# MCSPI register map
Vendor: Texas Instruments
Peripheral module from a debugger description file (folder am437x).
Registers are 32-bit, read-write, no defined reset value unless marked. A register's access mark holds for its fields unless they carry their own. Offsets are as the file gives them; lines under a group give offsets from that group; [hi:lo] are bit positions; {n}, {i} and the like mark numbered series; 'fields as' and 'values as' point back to an identical list; <NAME> marks a mode.

## MCSPI
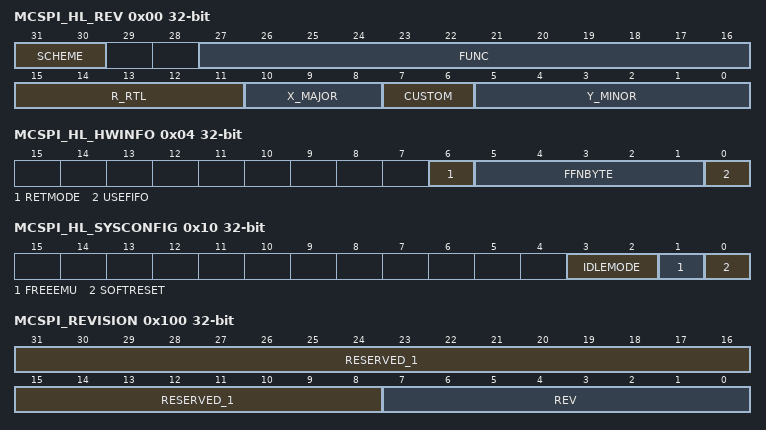
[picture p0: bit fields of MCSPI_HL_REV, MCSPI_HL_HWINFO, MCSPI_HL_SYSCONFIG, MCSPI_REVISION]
0x00 MCSPI_HL_REV ro — IP Revision Identifier (X.Y.R) Used by software to track features, bugs, and compatibility
  [31:30] SCHEME — Used to distinguish between old scheme and current.
    1=en_2_0x1 (Highlander 0.8 scheme); 0=en_1_0x0 (Legacy ASP or WTBU scheme)
  [27:16] FUNC — Function indicates a software compatible module family. [[br]]If there is no level of software compatibility a new Func number (and hence REVISION) should be assigned.
  [15:11] R_RTL — RTL Version (R), maintained by IP design owner. [[br]]RTL follows a numbering such as X.Y.R.Z which are explained in this table. [[br]]R changes ONLY when: (1) PDS uploads occur which may have been due to spec changes (2) Bug fixes occur (3) Resets to '0' when X or Y changes. [[br]]Design team has an internal 'Z' (customer invisible) number which increments on every drop that happens due to DV and RTL updates. [[br]]Z resets to 0 when R increments.
  [10:8] X_MAJOR — Major Revision (X), maintained by IP specification owner. [[br]]X changes ONLY when: (1) There is a major feature addition. [[br]]An example would be adding Master Mode to Utopia Level2. [[br]]The Func field (or Class/Type in old PID format) will remain the same. [[br]]X does NOT change due to: (1) Bug fixes (2) Change in feature parameters.
  [7:6] CUSTOM — Indicates a special version for a particular device. [[br]]Consequence of use may avoid use of standard Chip Support Library (CSL) / Drivers.
    0=en_1_0x0 (Non custom (standard) revision)
  [5:0] Y_MINOR — Minor Revision (Y), maintained by IP specification owner. [[br]]Y changes ONLY when: (1) Features are scaled (up or down). [[br]]Flexibility exists in that this feature scalability may either be represented in the Y change or a specific register in the IP that indicates which features are exactly available. [[br]](2) When feature creeps from Is-Not list to Is list. [[br]]But this may not be the case once it sees silicon[[br]] in which case X will change. [[br]]Y does NOT change due to: (1) Bug fixes (2) Typos or clarifications (3) major functional/feature change/addition/deletion. [[br]]Instead these changes may be reflected via R, S, X as applicable. [[br]]Spec owner maintains a customer-invisible number 'S' which changes due to: (1) Typos/clarifications (2) Bug documentation. [[br]]Note that this bug is not due to a spec change but due to implementation. [[br]]Nevertheless, the spec tracks the IP bugs. [[br]]An RTL release (say for silicon PG1.1) that occurs due to bug fix should document the corresponding spec number (X.Y.S) in its release notes.
0x04 MCSPI_HL_HWINFO ro — Information about the IP module's hardware configuration, i.e. typically the module's HDL generics (if any). Actual field format and encoding is up to the module's designer to decide.
  [6] RETMODE — This bit field indicates whether the retention mode is supported using the pin PIRFFRET.
    1=en_2_0x1 (Retention mode enabled); 0=en_1_0x0 (Retention mode disabled)
  [5:1] FFNBYTE — FIFO number of byte generic parameter This register defines the value of FFNBYTE generic parameter, only MSB bits from 8 down to 4 are taken into account.
    16=en_5_0x10 (FIFO 256 bytes depth); 8=en_4_0x8 (FIFO 128 bytes depth); 4=en_3_0x4 (FIFO 64 bytes depth); 2=en_2_0x2 (FIFO 32 bytes depth); 1=en_1_0x1 (FIFO 16 bytes depth)
  [0] USEFIFO — Use of a FIFO enable: This bit field indicates if a FIFO is integrated within controller design with its management.
    1=en_2_0x1 (FIFO and its management implemented in design with depth defined by FFNBYTE generic.); 0=en_1_0x0 (FIFO not implemented in design)
0x10 MCSPI_HL_SYSCONFIG access per field — Clock management configuration
  [3:2] IDLEMODE rw — Configuration of the local target state management mode. [[br]]By definition, target can handle read/write transaction as long as it is out of IDLE state.
    3=en_4_0x3 (Smart-idle wakeup-capable mode: local target's idle state eventually follows (acknowledges) the system's idle requests, depending on the IP module's internal requirements.IP module may generate (IRQ- or DMA-request-related) wakeup events when in idle state.Mode is only relevant if the appropriate IP module "swakeup" output(s) is (are) implemented.); 2=en_3_0x2 (Smart-idle mode: local target's idle state eventually follows (acknowledges) the system's idle requests, depending on the IP module's internal requirements.IP module shall not generate (IRQ- or DMA-request-related) wakeup events.); 1=en_2_0x1 (No-idle mode: local target never enters idle state.Backup mode, for debug only.); 0=en_1_0x0 (Force-idle mode: local target's idle state follows (acknowledges) the system's idle requests unconditionally, i.e. regardless of the IP module's internal requirements.Backup mode, for debug only.)
  [1] FREEEMU rw — Sensitivity to emulation (debug) suspend input signal.
    1=en_2_0x1 (IP module is not sensitive to emulation suspend); 0=en_1_0x0 (IP module is sensitive to emulation suspend)
  [0] SOFTRESET rw — Software reset. [[br]](Optional)
    1=en_4_0x1 (Initiate software reset); 1=en_3_0x1 (Reset (software or other) ongoing); 0=en_2_0x0 (No action); 0=en_1_0x0 (Reset done, no pending action)
0x100 MCSPI_REVISION ro — This register contains the hard coded RTL revision number.
  [31:8] RESERVED_1 — Reads returns 0
  [7:0] REV — IP revision [[br]][7:4] Major revision [[br]][3:0] Minor revision Examples: 0x10 for 1.0, 0x21 for 2.1
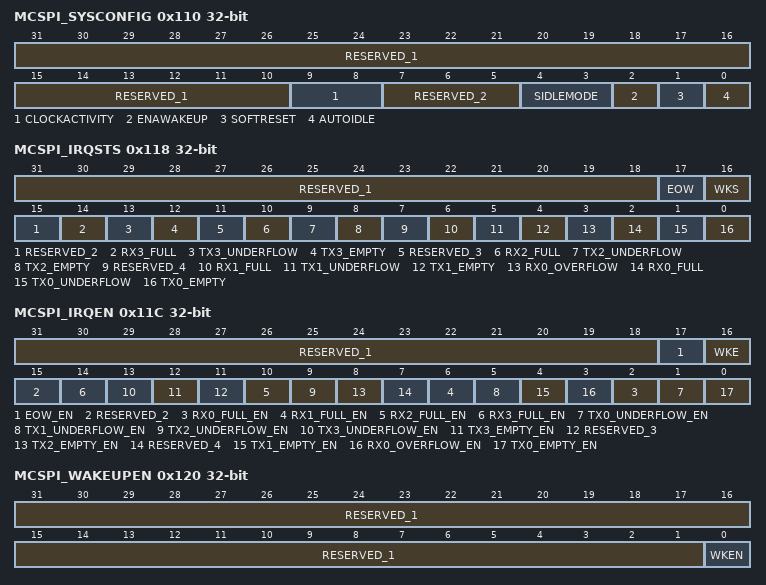
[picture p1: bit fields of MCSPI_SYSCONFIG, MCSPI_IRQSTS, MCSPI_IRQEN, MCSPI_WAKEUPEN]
0x110 MCSPI_SYSCONFIG — This register allows controlling various parameters of the OCP interface.
  [31:10] RESERVED_1 — Reads returns 0
  [9:8] CLOCKACTIVITY — Clocks activity during wake up mode period
    3=en_4_0x3 (OCP and Functional clocks are maintained.); 2=en_3_0x2 (Functional clock is maintained. OCP clock may be switched-off.); 1=en_2_0x1 (OCP clock is maintained. Functional clock may be switched-off.); 0=en_1_0x0 (OCP and Functional clocks may be switched off.)
  [7:5] RESERVED_2 — Reads returns 0
  [4:3] SIDLEMODE — Power management
    3=en_4_0x3 (If an idle request is detected, the module will switch to idle mode based on its internal activity, and the wake up capability can be used if the bit MCSPI_SYSCONFIG[EnaWakeUp] is set.); 2=en_3_0x2 (If an idle request is detected, the module will switch to idle mode based on its internal activity. The wake up capability cannot be used.); 1=en_2_0x1 (If an idle request is detected, the request is ignored and the module does not switch to wake up mode, and keeps on behaving normally.); 0=en_1_0x0 (If an idle request is detected, the McSPI acknowledges it unconditionally and goes in Inactive mode. Interrupt, DMA requests and wake up lines are unconditionally de-asserted and the module wakeup capability is deactivated even if the bit MCSPI_SYSCONFIG[EnaWakeUp] is set.)
  [2] ENAWAKEUP — WakeUp feature control
    1=en_2_0x1 (WakeUp capability is enabled); 0=en_1_0x0 (WakeUp capability is disabled)
  [1] SOFTRESET — Software reset. [[br]]During reads it always returns 0.
    1=en_2_0x1 ((write) Set this bit to 1 to trigger a module reset.The bit is automatically reset by the hardware.); 0=en_1_0x0 ((write) Normal mode)
  [0] AUTOIDLE — Internal OCP Clock gating strategy
    1=en_2_0x1 (Automatic OCP clock gating strategy is applied, based on the OCP interface activity); 0=en_1_0x0 (OCP clock is free-running)
0x114 MCSPI_SYSSTS ro — This register provides status information about the module excluding the interrupt status information
  [0] RESETDONE — Internal Reset Monitoring
    1=en_2_0x1 (Reset completed); 0=en_1_0x0 (Internal module reset is on-going)
0x118 MCSPI_IRQSTS — The interrupt status regroups all the status of the module internal events that can generate an interrupt
  [31:18] RESERVED_1 — Reads returns 0
  [17] EOW — End of word count event when a channel is enabled using the FIFO buffer and the channel had sent the number of SPI word defined by MCSPI_XFERLEVEL[WCNT]. [[br]]
    1=en_4_0x1 (Event is pending); 1=en_3_0x1 (Event status bit is reset); 0=en_2_0x0 (Event status bit unchanged); 0=en_1_0x0 (Event false)
  [16] WKS — Wake Up event in slave mode when an active control signal is detected on the SPIEN line programmed in the field MCSPI_CH0CONF[SPIENSLV]
    values as EOW
  [15] RESERVED_2 — Reads returns 0
  [14] RX3_FULL — Receiver register is full or almost full. [[br]]Only when Channel 3 is enabled
    values as EOW
  [13] TX3_UNDERFLOW — Transmitter register underflow. [[br]]Only when Channel 3 is enabled. [[br]]The transmitter register is empty (not updated by Host or DMA with new data) before its time slot assignment. [[br]]Exception: No TX_underflow event when no data has been loaded into the transmitter register since channel has been enabled. [[br]]
    values as EOW
  [12] TX3_EMPTY — Transmitter register is empty or almost empty. [[br]]Note: Enabling the channel automatically rises this event. [[br]]
    values as EOW
  [11] RESERVED_3 — Reads returns 0
  [10] RX2_FULL — Receiver register full or almost full. [[br]]Channel 2
    values as EOW
  [9] TX2_UNDERFLOW — Transmitter register underflow. [[br]]Channel 2
    values as EOW
  [8] TX2_EMPTY — Transmitter register empty or almost empty. [[br]]Channel 2
    values as EOW
  [7] RESERVED_4 — Reads returns 0
  [6] RX1_FULL — Receiver register full or almost full. [[br]]Channel 1
    values as EOW
  [5] TX1_UNDERFLOW — Transmitter register underflow. [[br]]Channel 1
    values as EOW
  [4] TX1_EMPTY — Transmitter register empty or almost empty. [[br]]Channel 1
    values as EOW
  [3] RX0_OVERFLOW — Receiver register overflow (slave mode only). [[br]]Channel 0
    values as EOW
  [2] RX0_FULL — Receiver register full or almost full. [[br]]Channel 0
    values as EOW
  [1] TX0_UNDERFLOW — Transmitter register underflow. [[br]]Channel 0
    values as EOW
  [0] TX0_EMPTY — Transmitter register empty or almost empty. [[br]]Channel 0
    values as EOW
0x11C MCSPI_IRQEN — This register allows to enable/disable the module internal sources of interrupt, on an event-by-event basis.
  [31:18] RESERVED_1 — Reads return 0
  [17] EOW_EN — End of Word count Interrupt Enable.
    1=en_2_0x1 (Interrupt enabled); 0=en_1_0x0 (Interrupt disabled)
  [16] WKE — Wake Up event interrupt Enable in slave mode when an active control signal is detected on the SPIEN line programmed in the field MCSPI_CH0CONF[SPIENSLV]
    values as EOW_EN
  [15] RESERVED_2 — Reads returns 0
  [4n+2] RX{n}_FULL_EN (n=0..3) — Receiver register Full Interrupt Enable. [[br]]Ch {n}
    values as EOW_EN
  [4n+1] TX{n}_UNDERFLOW_EN (n=0..3) — Transmitter register Underflow Interrupt Enable. [[br]]Ch {n}
    values as EOW_EN
  [12] TX3_EMPTY_EN — Transmitter register Empty Interrupt Enable. [[br]]Ch3
    values as EOW_EN
  [11] RESERVED_3 — Reads return 0
  [8] TX2_EMPTY_EN — Transmitter register Empty Interrupt Enable. [[br]]Ch 2
    values as EOW_EN
  [7] RESERVED_4 — Reads return 0
  [4] TX1_EMPTY_EN — Transmitter register Empty Interrupt Enable. [[br]]Ch 1
    values as EOW_EN
  [3] RX0_OVERFLOW_EN — Receiver register Overflow Interrupt Enable. [[br]]Ch 0
    values as EOW_EN
  [0] TX0_EMPTY_EN — Transmitter register Empty Interrupt Enable. [[br]]Ch 0
    values as EOW_EN
0x120 MCSPI_WAKEUPEN — The wakeup enable register allows to enable/disable the module internal sources of wakeup on event-by-event basis.
  [31:1] RESERVED_1 — Reads returns 0
  [0] WKEN — WakeUp functionality in slave mode when an active control signal is detected on the SPIEN line programmed in the field MCSPI_CH0CONF[SPIENSLV]
    1=en_2_0x1 (The event is allowed to wakeup the system if the global control bit MCSPI_SYSCONF[EnaWakeUp] is set.); 0=en_1_0x0 (The event is not allowed to wakeup the system, even if the global control bit MCSPI_SYSCONF[EnaWakeUp] is set.)
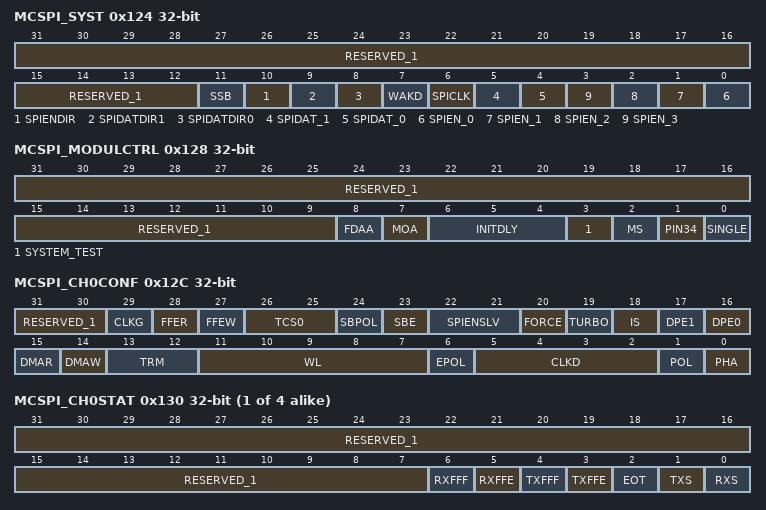
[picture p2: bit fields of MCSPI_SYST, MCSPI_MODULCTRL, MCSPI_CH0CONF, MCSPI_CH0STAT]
0x124 MCSPI_SYST — This register is used to check the correctness of the system interconnect either internally to peripheral bus, or externally to device IO pads, when the module is configured in system test (SYSTEST) mode.
  [31:12] RESERVED_1 — Reads returns 0
  [11] SSB — Set status bit
    1=en_2_0x1 (Force to 1 all status bits of MCSPI_IRQSTATUS register. Writing 1 into this bit sets to 1 all status bits contained in the MCSPI_IRQSTATUS register.); 0=en_1_0x0 (No action. Writing 0 does not clear already set status bits; This bit must be cleared prior attempting to clear a status bit of the MCSPI_IRQSTATUS register.)
  [10] SPIENDIR — Set the direction of the SPIEN[[br]][3:0] lines and SPICLK line
    1=en_2_0x1 (input (as in slave mode)); 0=en_1_0x0 (output (as in master mode))
  [9] SPIDATDIR1 — Set the direction of the SPIDAT[1]
    1=en_2_0x1 (input); 0=en_1_0x0 (output)
  [8] SPIDATDIR0 — Set the direction of the SPIDAT[0]
    1=en_2_0x1 (input); 0=en_1_0x0 (output)
  [7] WAKD — SWAKEUP output (signal data value of internal signal to system). [[br]]The signal is driven high or low according to the value written into this register bit.
    1=en_2_0x1 (The pin is driven high.); 0=en_1_0x0 (The pin is driven low.)
  [6] SPICLK — SPICLK line (signal data value) If MCSPI_SYST[SPIENDIR] = 1 (input mode direction), this bit returns the value on the CLKSPI line (high or low), and a write into this bit has no effect. [[br]]If MCSPI_SYST[SPIENDIR] = 0 (output mode direction), the CLKSPI line is driven high or low according to the value written into this register.
  [5] SPIDAT_1 — SPIDAT[1] line (signal data value) If MCSPI_SYST[SPIDATDIR1] = 0 (output mode direction), the SPIDAT[1] line is driven high or low according to the value written into this register. [[br]]If MCSPI_SYST[SPIDATDIR1] = 1 (input mode direction), this bit returns the value on the SPIDAT[1] line (high or low), and a write into this bit has no effect. [[br]]
  [4] SPIDAT_0 — SPIDAT[0] line (signal data value) If MCSPI_SYST[SPIDATDIR0] = 0 (output mode direction), the SPIDAT[0] line is driven high or low according to the value written into this register. [[br]]If MCSPI_SYST[SPIDATDIR0] = 1 (input mode direction), this bit returns the value on the SPIDAT[0] line (high or low), and a write into this bit has no effect. [[br]]
  [n] SPIEN_{n} (n=0..3) — SPIEN[{n}] line (signal data value) If MCSPI_SYST[SPIENDIR] = 0 (output mode direction), the SPIENT[{n}] line is driven high or low according to the value written into this register. [[br]]If MCSPI_SYST[SPIENDIR] = 1 (input mode direction), this bit returns the value on the SPIEN[{n}] line (high or low), and a write into this bit has no effect.
0x128 MCSPI_MODULCTRL — This register is dedicated to the configuration of the serial port interface.
  [31:9] RESERVED_1 — Reads returns 0
  [8] FDAA — FIFO DMA Address [[br]]256-bit aligned This register is used when a FIFO is managed by the module and DMA connected to the controller provides only 256 bit aligned address. [[br]]If this bit is set the enabled channel which uses the FIFO has its datas managed through MCSPI_DAFTX and MCSPI_DAFRX registers instead of MCSPI_TX(i) and MCSPI_RX(i) registers.
    1=en_2_0x1 (FIFO data managed by MCSPI_DAFTX and MCSPI_DAFRX registers.); 0=en_1_0x0 (FIFO data managed by MCSPI_TX(i) and MCSPI_RX(i) registers.)
  [7] MOA — Multiple word ocp access: This register can only be used when a channel is enabled using a FIFO. [[br]]It allows the system to perform multiple SPI word access for a single [[br]]32-bit OCP word access. [[br]]This is possible for WL less than 16.
    1=en_2_0x1 (Multiple word access enabled with FIFO); 0=en_1_0x0 (Multiple word access disabled)
  [6:4] INITDLY — Initial spi delay for first transfer: This register is an option only available in SINGLE master mode, The controller waits for a delay to transmit the first spi word after channel enabled and corresponding TX register filled. [[br]]This Delay is based on SPI output frequency clock, No clock output provided to the boundary and chip select is not active in 4 pin mode within this period. [[br]]
    4=en_5_0x4 (32ClkDly : The controller wait 32 spi bus clock); 3=en_4_0x3 (16ClkDly : The controller wait 16 spi bus clock); 2=en_3_0x2 (8ClkDly : The controller wait 8 spi bus clock); 1=en_2_0x1 (4ClkDly : The controller wait 4 spi bus clock); 0=en_1_0x0 (No delay for first spi transfer.)
  [3] SYSTEM_TEST — Enables the system test mode
    1=en_2_0x1 (System test mode (SYSTEST)); 0=en_1_0x0 (Functional mode)
  [2] MS — Master/ Slave
    1=en_2_0x1 (Slave - The module receives the SPICLK and SPIEN[3:0]); 0=en_1_0x0 (Master - The module generates the SPICLK and SPIEN[3:0])
  [1] PIN34 — Pin mode selection: This register is used to configure the SPI pin mode, in master or slave mode. [[br]]If asserted the controller only use SIMO,SOMI and SPICLK clock pin for spi transfers.
    1=en_2_0x1 (3PinMode : SPIEN is used as a chip select.); 0=en_1_0x0 (4PinMode : SPIEN is not used.In this mode all related option to chip select have no meaning.)
  [0] SINGLE — Single channel / Multi Channel (master mode only)
    1=en_2_0x1 (Only one channel will be used in master mode. This bit must be set in Force SPIEN mode.); 0=en_1_0x0 (More than one channel will be used in master mode.)
0x12C MCSPI_CH0CONF access per field — This register is dedicated to the configuration of the channel 0
  [31:30] RESERVED_1 ro — read returns 0
  [29] CLKG rw — Clock divider granularity This register defines the granularity of channel clock divider: power of two or one clock cycle granularity. [[br]]When this bit is set the register MCSPI_CHCTRL[EXTCLK] must be configured to reach a maximum of 4096 clock divider ratio. [[br]]Then The clock divider ratio is a concatenation of MCSPI_CHCONF[CLKD] and MCSPI_CHCTRL[EXTCLK] values
    1=en_2_0x1 (One clock cycle ganularity); 0=en_1_0x0 (Clock granularity of power of two)
  [28] FFER rw — FIFO enabled for receive:Only one channel can have this bit field set.
    1=en_2_0x1 (The buffer is used to receive data.); 0=en_1_0x0 (The buffer is not used to receive data.)
  [27] FFEW rw — FIFO enabled for Transmit:Only one channel can have this bit field set.
    1=en_2_0x1 (The buffer is used to transmit data.); 0=en_1_0x0 (The buffer is not used to transmit data.)
  [26:25] TCS0 rw — Chip Select Time Control This [[br]]2-bits field defines the number of interface clock cycles between CS toggling and first or last edge of SPI clock.
    3=en_4_0x3 (3.5 clock cycle); 2=en_3_0x2 (2.5 clock cycle); 1=en_2_0x1 (1.5 clock cycle); 0=en_1_0x0 (0.5 clock cycle)
  [24] SBPOL rw — Start bit polarity
    1=en_2_0x1 (Start bit polarity is held to 1 during SPI transfer.); 0=en_1_0x0 (Start bit polarity is held to 0 during SPI transfer.)
  [23] SBE rw — Start bit enable for SPI transfer
    1=en_2_0x1 (Start bit D/CX added before SPI transfer polarity is defined by MCSPI_CH0CONF[SBPOL]); 0=en_1_0x0 (Default SPI transfer length as specified by WL bit field)
  [22:21] SPIENSLV rw — Channel 0 only and slave mode only: SPI slave select signal detection. [[br]]Reserved bits for other cases.
    {v}=en_{v+1}_{0x0+v} (Detection enabled only on SPIEN[{v}]) (v=0..3)
  [20] FORCE rw — Manual SPIEN assertion to keep SPIEN active between SPI words. [[br]](single channel master mode only)
    1=en_2_0x1 (Writing 1 into this bit drives high the SPIEN line when MCSPI_CHCONF(i)[EPOL]=0, and drives it low when MCSPI_CHCONF(i)[EPOL]=1); 0=en_1_0x0 (Writing 0 into this bit drives low the SPIEN line when MCSPI_CHCONF(i)[EPOL]=0, and drives it high when MCSPI_CHCONF(i)[EPOL]=1.)
  [19] TURBO rw — Turbo mode
    1=en_2_0x1 (Turbo is activated to maximize the throughput for multi SPI words transfer.); 0=en_1_0x0 (Turbo is deactivated (recommended for single SPI word transfer))
  [18] IS rw — Input Select
    1=en_2_0x1 (Data Line1 (SPIDAT[1]) selected for reception); 0=en_1_0x0 (Data Line0 (SPIDAT[0]) selected for reception.)
  [17] DPE1 rw — Transmission Enable for data line 1 (SPIDATAGZEN[1])
    1=en_2_0x1 (No transmission on Data Line1 (SPIDAT[1])); 0=en_1_0x0 (Data Line1 (SPIDAT[1]) selected for transmission)
  [16] DPE0 rw — Transmission Enable for data line 0 (SPIDATAGZEN[0])
    1=en_2_0x1 (No transmission on Data Line0 (SPIDAT[0])); 0=en_1_0x0 (Data Line0 (SPIDAT[0]) selected for transmission)
  [15] DMAR rw — DMA Read request The DMA Read request line is asserted when the channel is enabled and a new data is available in the receive register of the channel. [[br]]The DMA Read request line is deasserted on read completion of the receive register of the channel.
    1=en_2_0x1 (DMA Read Request enabled); 0=en_1_0x0 (DMA Read Request disabled)
  [14] DMAW rw — DMA Write request. [[br]]The DMA Write request line is asserted when The channel is enabled and the transmitter register of the channel is empty. [[br]]The DMA Write request line is deasserted on load completion of the transmitter register of the channel.
    1=en_2_0x1 (DMA Write Request enabled); 0=en_1_0x0 (DMA Write Request disabled)
  [13:12] TRM rw — Transmit/Receive modes
    3=en_4_0x3 (Reserved); 2=en_3_0x2 (Transmit only mode); 1=en_2_0x1 (Receive only mode); 0=en_1_0x0 (Transmit and Receive mode)
  [11:7] WL rw — SPI word length
    {v}=en_{v+1}_{0x0+v} ({v+1}bits : The SPI word is {v+1}-bits long) (v=3..31); 2=en_3_0x2 (Reserved); 1=en_2_0x1 (Reserved); 0=en_1_0x0 (Reserved)
  [6] EPOL rw — SPIEN polarity
    1=en_2_0x1 (SPIEN is held low during the active state.); 0=en_1_0x0 (SPIEN is held high during the active state.)
  [5:2] CLKD rw — Frequency divider for SPICLK. [[br]](only when the module is a Master SPI device). [[br]]A programmable clock divider divides the SPI reference clock (CLKSPIREF) with a [[br]]4-bit value, and results in a new clock SPICLK available to shift-in and shift-out data. [[br]]By default the clock divider ratio has a power of two granularity when MCSPI_CHCONF[CLKG] is cleared, Otherwise this register is the 4 LSB bit of a [[br]]12-bit register concatenated with clock divider extension MCSPI_CHCTRL[EXTCLK] register.The value description below defines the clock ratio when MCSPI_CHCONF[CLKG] is set to 0.
    15=en_16_0xF (32768); 14=en_15_0xE (16384); 13=en_14_0xD (8192); 12=en_13_0xC (4096); 11=en_12_0xB (2048); 10=en_11_0xA (1024); 9=en_10_0x9 (512); 8=en_9_0x8 (256); 7=en_8_0x7 (128); 6=en_7_0x6 (64); 5=en_6_0x5 (32); 4=en_5_0x4 (16); 3=en_4_0x3 (8); 2=en_3_0x2 (4); 1=en_2_0x1 (2); 0=en_1_0x0 (1)
  [1] POL rw — SPICLK polarity
    1=en_2_0x1 (SPICLK is held low during the active state); 0=en_1_0x0 (SPICLK is held high during the active state)
  [0] PHA rw — SPICLK phase
    1=en_2_0x1 (Data are latched on even numbered edges of SPICLK.); 0=en_1_0x0 (Data are latched on odd numbered edges of SPICLK.)
{0x130+0x14*i} MCSPI_CH{i}STAT ro (i=0..3) — This register provides status information about transmitter and receiver registers of channel {i}
  [31:7] RESERVED_1 — Read returns 0
  [6] RXFFF — Channel "i" FIFO Receive Buffer Full Status
    1=en_2_0x1 (FIFO Receive Buffer is full); 0=en_1_0x0 (FIFO Receive Buffer is not full)
  [5] RXFFE — Channel "i" FIFO Receive Buffer Empty Status
    1=en_2_0x1 (FIFO Receive Buffer is empty); 0=en_1_0x0 (FIFO Receive Buffer is not empty)
  [4] TXFFF — Channel "i" FIFO Transmit Buffer Full Status
    1=en_2_0x1 (FIFO Transmit Buffer is full); 0=en_1_0x0 (FIFO Transmit Buffer is not full)
  [3] TXFFE — Channel "i" FIFO Transmit Buffer Empty Status
    1=en_2_0x1 (FIFO Transmit Buffer is empty); 0=en_1_0x0 (FIFO Transmit Buffer is not empty)
  [2] EOT — Channel "i" End of transfer Status. [[br]]The definitions of beginning and end of transfer vary with master versus slave and the transfer format (Transmit/Receive modes, Turbo mode). [[br]]See dedicated chapters for details.
    1=en_2_0x1 (This flag is automatically set to one at the end of an SPI transfer.); 0=en_1_0x0 (This flag is automatically cleared when the shift register is loaded with the data from the transmitter register (beginning of transfer).)
  [1] TXS — Channel "i" Transmitter Register Status
    1=en_2_0x1 (Register is empty); 0=en_1_0x0 (Register is full)
  [0] RXS — Channel "i" Receiver Register Status
    1=en_2_0x1 (Register is full); 0=en_1_0x0 (Register is empty)
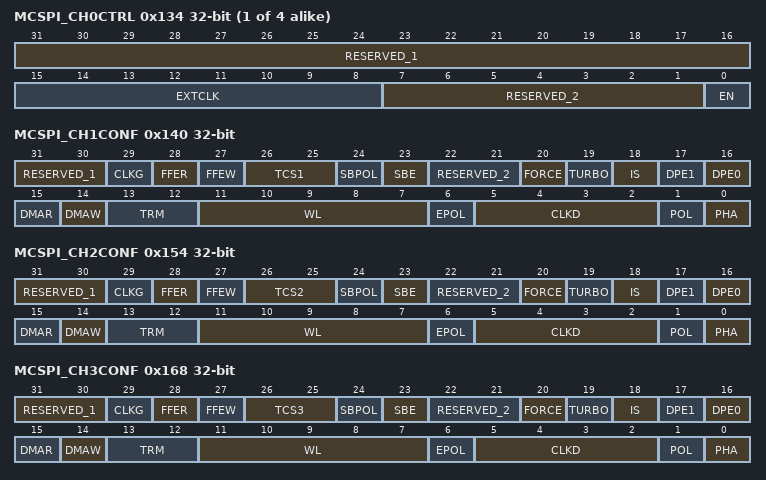
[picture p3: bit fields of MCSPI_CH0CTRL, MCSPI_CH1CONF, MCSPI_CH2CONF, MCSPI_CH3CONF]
{0x134+0x14*i} MCSPI_CH{i}CTRL (i=0..3) — This register is dedicated to enable the channel {i}
  [31:16] RESERVED_1 — Read returns 0
  [15:8] EXTCLK — Clock ratio extension: This register is used to concatenate with MCSPI_CHCONF[CLKD] register for clock ratio only when granularity is one clock cycle (MCSPI_CHCONF[CLKG] set to 1). [[br]]Then the max value reached is 4096 clock divider ratio.
    255=en_3_0xFF (Clock ratio is CLKD + 1 + 4080); 1=en_2_0x1 (Clock ratio is CLKD + 1 + 16); 0=en_1_0x0 (Clock ratio is CLKD + 1)
  [7:1] RESERVED_2 — Read returns 0
  [0] EN — Channel Enable
    1=en_2_0x1 (Channel "i" is active); 0=en_1_0x0 (Channel "i" is not active)
{0x138+0x14*i} MCSPI_TX{i} (i=0..3) — This register contains a single SPI word to transmit on the serial link, what ever SPI word length is.
  [31:0] TDATA — Channel {i} Data to transmit
{0x13C+0x14*i} MCSPI_RX{i} ro (i=0..3) — This register contains a single SPI word received through the serial link, what ever SPI word length is.
  [31:0] RDATA — Channel {i} Received Data
0x140 MCSPI_CH1CONF — This register is dedicated to the configuration of the channel.
  [31:30] RESERVED_1 — read returns 0
  [29] CLKG — Clock divider granularity This register defines the granularity of channel clock divider: power of two or one clock cycle granularity. [[br]]When this bit is set the register MCSPI_CHCTRL[EXTCLK] must be configured to reach a maximum of 4096 clock divider ratio. [[br]]Then The clock divider ratio is a concatenation of MCSPI_CHCONF[CLKD] and MCSPI_CHCTRL[EXTCLK] values
    values as MCSPI_CH0CONF.CLKG
  [28] FFER — FIFO enabled for receive:Only one channel can have this bit field set.
    values as MCSPI_CH0CONF.FFER
  [27] FFEW — FIFO enabled for Transmit:Only one channel can have this bit field set.
    values as MCSPI_CH0CONF.FFEW
  [26:25] TCS1 — Chip Select Time Control This [[br]]2-bits field defines the number of interface clock cycles between CS toggling and first or last edge of SPI clock.
    values as MCSPI_CH0CONF.TCS0
  [24] SBPOL — Start bit polarity
    values as MCSPI_CH0CONF.SBPOL
  [23] SBE — Start bit enable for SPI transfer
    1=en_2_0x1 (Start bit D/CX added before SPI transfer polarity is defined by MCSPI_CH1CONF[SBPOL]); 0=en_1_0x0 (Default SPI transfer length as specified by WL bit field)
  [22:21] RESERVED_2 — read returns 0
  [20] FORCE — Manual SPIEN assertion to keep SPIEN active between SPI words. [[br]](single channel master mode only)
    values as MCSPI_CH0CONF.FORCE
  [19] TURBO — Turbo mode
    values as MCSPI_CH0CONF.TURBO
  [18] IS — Input Select
    values as MCSPI_CH0CONF.IS
  [17] DPE1 — Transmission Enable for data line 1 (SPIDATAGZEN[1])
    values as MCSPI_CH0CONF.DPE1
  [16] DPE0 — Transmission Enable for data line 0 (SPIDATAGZEN[0])
    values as MCSPI_CH0CONF.DPE0
  [15] DMAR — DMA Read request The DMA Read request line is asserted when the channel is enabled and a new data is available in the receive register of the channel. [[br]]The DMA Read request line is deasserted on read completion of the receive register of the channel.
    values as MCSPI_CH0CONF.DMAR
  [14] DMAW — DMA Write request. [[br]]The DMA Write request line is asserted when The channel is enabled and the transmitter register of the channel is empty. [[br]]The DMA Write request line is deasserted on load completion of the transmitter register of the channel.
    values as MCSPI_CH0CONF.DMAW
  [13:12] TRM — Transmit/Receive modes
    values as MCSPI_CH0CONF.TRM
  [11:7] WL — SPI word length
    values as MCSPI_CH0CONF.WL
  [6] EPOL — SPIEN polarity
    values as MCSPI_CH0CONF.EPOL
  [5:2] CLKD — Frequency divider for SPICLK. [[br]](only when the module is a Master SPI device). [[br]]A programmable clock divider divides the SPI reference clock (CLKSPIREF) with a [[br]]4-bit value, and results in a new clock SPICLK available to shift-in and shift-out data. [[br]]By default the clock divider ratio has a power of two granularity when MCSPI_CHCONF[CLKG] is cleared, Otherwise this register is the 4 LSB bit of a [[br]]12-bit register concatenated with clock divider extension MCSPI_CHCTRL[EXTCLK] register.The value description below defines the clock ratio when MCSPI_CHCONF[CLKG] is set to 0.
    values as MCSPI_CH0CONF.CLKD
  [1] POL — SPICLK polarity
    values as MCSPI_CH0CONF.POL
  [0] PHA — SPICLK phase
    values as MCSPI_CH0CONF.PHA
0x154 MCSPI_CH2CONF — This register is dedicated to the configuration of the channel 2
  [31:30] RESERVED_1 — read returns 0
  [29] CLKG — Clock divider granularity This register defines the granularity of channel clock divider: power of two or one clock cycle granularity. [[br]]When this bit is set the register MCSPI_CHCTRL[EXTCLK] must be configured to reach a maximum of 4096 clock divider ratio. [[br]]Then The clock divider ratio is a concatenation of MCSPI_CHCONF[CLKD] and MCSPI_CHCTRL[EXTCLK] values
    values as MCSPI_CH0CONF.CLKG
  [28] FFER — FIFO enabled for receive:Only one channel can have this bit field set.
    values as MCSPI_CH0CONF.FFER
  [27] FFEW — FIFO enabled for Transmit:Only one channel can have this bit field set.
    values as MCSPI_CH0CONF.FFEW
  [26:25] TCS2 — Chip Select Time Control This [[br]]2-bits field defines the number of interface clock cycles between CS toggling and first or last edge of SPI clock.
    values as MCSPI_CH0CONF.TCS0
  [24] SBPOL — Start bit polarity
    values as MCSPI_CH0CONF.SBPOL
  [23] SBE — Start bit enable for SPI transfer
    1=en_2_0x1 (Start bit D/CX added before SPI transfer polarity is defined by MCSPI_CH2CONF[SBPOL]); 0=en_1_0x0 (Default SPI transfer length as specified by WL bit field)
  [22:21] RESERVED_2 — read returns 0
  [20] FORCE — Manual SPIEN assertion to keep SPIEN active between SPI words. [[br]](single channel master mode only)
    values as MCSPI_CH0CONF.FORCE
  [19] TURBO — Turbo mode
    values as MCSPI_CH0CONF.TURBO
  [18] IS — Input Select
    values as MCSPI_CH0CONF.IS
  [17] DPE1 — Transmission Enable for data line 1 (SPIDATAGZEN[1])
    values as MCSPI_CH0CONF.DPE1
  [16] DPE0 — Transmission Enable for data line 0 (SPIDATAGZEN[0])
    values as MCSPI_CH0CONF.DPE0
  [15] DMAR — DMA Read request The DMA Read request line is asserted when the channel is enabled and a new data is available in the receive register of the channel. [[br]]The DMA Read request line is deasserted on read completion of the receive register of the channel.
    values as MCSPI_CH0CONF.DMAR
  [14] DMAW — DMA Write request. [[br]]The DMA Write request line is asserted when The channel is enabled and the transmitter register of the channel is empty. [[br]]The DMA Write request line is deasserted on load completion of the transmitter register of the channel.
    values as MCSPI_CH0CONF.DMAW
  [13:12] TRM — Transmit/Receive modes
    values as MCSPI_CH0CONF.TRM
  [11:7] WL — SPI word length
    values as MCSPI_CH0CONF.WL
  [6] EPOL — SPIEN polarity
    values as MCSPI_CH0CONF.EPOL
  [5:2] CLKD — Frequency divider for SPICLK. [[br]](only when the module is a Master SPI device). [[br]]A programmable clock divider divides the SPI reference clock (CLKSPIREF) with a [[br]]4-bit value, and results in a new clock SPICLK available to shift-in and shift-out data. [[br]]By default the clock divider ratio has a power of two granularity when MCSPI_CHCONF[CLKG] is cleared, Otherwise this register is the 4 LSB bit of a [[br]]12-bit register concatenated with clock divider extension MCSPI_CHCTRL[EXTCLK] register.The value description below defines the clock ratio when MCSPI_CHCONF[CLKG] is set to 0.
    values as MCSPI_CH0CONF.CLKD
  [1] POL — SPICLK polarity
    values as MCSPI_CH0CONF.POL
  [0] PHA — SPICLK phase
    values as MCSPI_CH0CONF.PHA
0x168 MCSPI_CH3CONF — This register is dedicated to the configuration of the channel 3
  [31:30] RESERVED_1 — read returns 0
  [29] CLKG — Clock divider granularity This register defines the granularity of channel clock divider: power of two or one clock cycle granularity. [[br]]When this bit is set the register MCSPI_CHCTRL[EXTCLK] must be configured to reach a maximum of 4096 clock divider ratio. [[br]]Then The clock divider ratio is a concatenation of MCSPI_CHCONF[CLKD] and MCSPI_CHCTRL[EXTCLK] values
    values as MCSPI_CH0CONF.CLKG
  [28] FFER — FIFO enabled for receive:Only one channel can have this bit field set.
    values as MCSPI_CH0CONF.FFER
  [27] FFEW — FIFO enabled for Transmit:Only one channel can have this bit field set.
    values as MCSPI_CH0CONF.FFEW
  [26:25] TCS3 — Chip Select Time Control This [[br]]2-bits field defines the number of interface clock cycles between CS toggling and first or last edge of SPI clock.
    values as MCSPI_CH0CONF.TCS0
  [24] SBPOL — Start bit polarity
    values as MCSPI_CH0CONF.SBPOL
  [23] SBE — Start bit enable for SPI transfer
    1=en_2_0x1 (Start bit D/CX added before SPI transfer polarity is defined by MCSPI_CH3CONF[SBPOL]); 0=en_1_0x0 (Default SPI transfer length as specified by WL bit field)
  [22:21] RESERVED_2 — read returns 0
  [20] FORCE — Manual SPIEN assertion to keep SPIEN active between SPI words. [[br]](single channel master mode only)
    values as MCSPI_CH0CONF.FORCE
  [19] TURBO — Turbo mode
    values as MCSPI_CH0CONF.TURBO
  [18] IS — Input Select
    values as MCSPI_CH0CONF.IS
  [17] DPE1 — Transmission Enable for data line 1 (SPIDATAGZEN[1])
    values as MCSPI_CH0CONF.DPE1
  [16] DPE0 — Transmission Enable for data line 0 (SPIDATAGZEN[0])
    values as MCSPI_CH0CONF.DPE0
  [15] DMAR — DMA Read request The DMA Read request line is asserted when the channel is enabled and a new data is available in the receive register of the channel. [[br]]The DMA Read request line is deasserted on read completion of the receive register of the channel.
    values as MCSPI_CH0CONF.DMAR
  [14] DMAW — DMA Write request. [[br]]The DMA Write request line is asserted when The channel is enabled and the transmitter register of the channel is empty. [[br]]The DMA Write request line is deasserted on load completion of the transmitter register of the channel.
    values as MCSPI_CH0CONF.DMAW
  [13:12] TRM — Transmit/Receive modes
    values as MCSPI_CH0CONF.TRM
  [11:7] WL — SPI word length
    values as MCSPI_CH0CONF.WL
  [6] EPOL — SPIEN polarity
    values as MCSPI_CH0CONF.EPOL
  [5:2] CLKD — Frequency divider for SPICLK. [[br]](only when the module is a Master SPI device). [[br]]A programmable clock divider divides the SPI reference clock (CLKSPIREF) with a [[br]]4-bit value, and results in a new clock SPICLK available to shift-in and shift-out data. [[br]]By default the clock divider ratio has a power of two granularity when MCSPI_CHCONF[CLKG] is cleared, Otherwise this register is the 4 LSB bit of a [[br]]12-bit register concatenated with clock divider extension MCSPI_CHCTRL[EXTCLK] register.The value description below defines the clock ratio when MCSPI_CHCONF[CLKG] is set to 0.
    values as MCSPI_CH0CONF.CLKD
  [1] POL — SPICLK polarity
    values as MCSPI_CH0CONF.POL
  [0] PHA — SPICLK phase
    values as MCSPI_CH0CONF.PHA
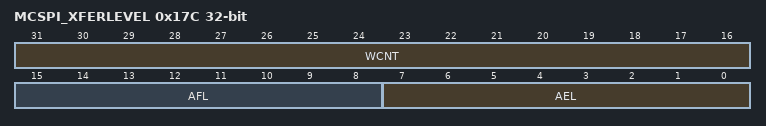
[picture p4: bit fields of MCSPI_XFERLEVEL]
0x17C MCSPI_XFERLEVEL — This register provides transfer levels needed while using FIFO buffer during transfer.
  [31:16] WCNT — Spi word counterThis register holds the programmable value of number of SPI word to be transferred on channel which is using the FIFO buffer.When transfer had started, a read back in this register returns the current SPI word transfer index.
    0xFFFF=en_4_0xFFFF (65535word : 65535 spi word); 0xFFFE=en_3_0xFFFE (65534word : 65534 spi word); 1=en_2_0x1 (1word : one word); 0=en_1_0x0 (Counter not used)
  [15:8] AFL — Buffer Almost Full This register holds the programmable almost full level value used to determine almost full buffer condition. [[br]]If the user wants an interrupt or a DMA read request to be issued during a receive operation when the data buffer holds at least n bytes, then the buffer MCSPI_MODULCTRL[AFL] must be set with n-1.The size of this register is defined by the generic parameter FFNBYTE.
    255=en_4_0xFF (256bytes : 256bytes); 254=en_3_0xFE (255bytes : 255bytes); 1=en_2_0x1 (2bytes : 2 bytes); 0=en_1_0x0 (1byte : one byte)
  [7:0] AEL — Buffer Almost EmptyThis register holds the programmable almost empty level value used to determine almost empty buffer condition. [[br]]If the user wants an interrupt or a DMA write request to be issued during a transmit operation when the data buffer is able to receive n bytes, then the buffer MCSPI_MODULCTRL[AEL] must be set with n-1.
    255=en_4_0xFF (256bytes : 256bytes); 254=en_3_0xFE (255bytes : 255 bytes); 1=en_2_0x1 (2bytes : 2 bytes); 0=en_1_0x0 (1byte : one byte)
0x180 MCSPI_DAFTX — This register contains the SPI words to transmit on the serial link when FIFO used and DMA address is aligned on 256 bit.This register is an image of one of MCSPI_TX(i) register corresponding to the channel which have its FIFO enabled.
  [31:0] DAFTDATA — FIFO Data to transmit with DMA 256 bit aligned address. [[br]]This Register is only is used when MCSPI_MODULCTRL[FDAA] is set to "1" and only one of the MCSPI_CH(i)CONF[FFEW] of enabled channels is set. [[br]]If these conditions are not respected any access to this register return a null value.
0x1A0 MCSPI_DAFRX ro — This register contains the SPI words to received on the serial link when FIFO used and DMA address is aligned on 256 bit.This register is an image of one of MCSPI_RX(i) register corresponding to the channel which have its FIFO enabled.
  [31:0] DAFRDATA — FIFO Data to transmit with DMA 256 bit aligned address. [[br]]This Register is only is used when MCSPI_MODULCTRL[FDAA] is set to "1" and only one of the MCSPI_CH(i)CONF[FFEW] of enabled channels is set. [[br]]If these conditions are not respected any access to this register return a null value.
